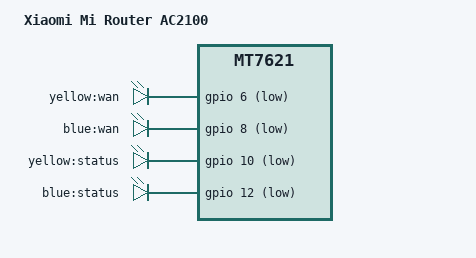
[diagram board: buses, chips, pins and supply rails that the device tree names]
// SPDX-License-Identifier: GPL-2.0-or-later OR MIT

#include "mt7621_xiaomi_router-ac2100.dtsi"

/ {
	compatible = "xiaomi,mi-router-ac2100", "mediatek,mt7621-soc";
	model = "Xiaomi Mi Router AC2100";

	aliases {
		led-boot = &led_status_yellow;
		led-failsafe = &led_status_yellow;
		led-running = &led_status_blue;
		led-upgrade = &led_status_blue;
		label-mac-device = &gmac0;
	};

	leds {
		compatible = "gpio-leds";

		wan_yellow {
			label = "yellow:wan";
			gpios = <&gpio 6 GPIO_ACTIVE_LOW>;
		};

		wan_blue {
			label = "blue:wan";
			gpios = <&gpio 8 GPIO_ACTIVE_LOW>;
		};

		led_status_yellow: status_yellow {
			label = "yellow:status";
			gpios = <&gpio 10 GPIO_ACTIVE_LOW>;
		};

		led_status_blue: status_blue {
			label = "blue:status";
			gpios = <&gpio 12 GPIO_ACTIVE_LOW>;
		};
	};
};
